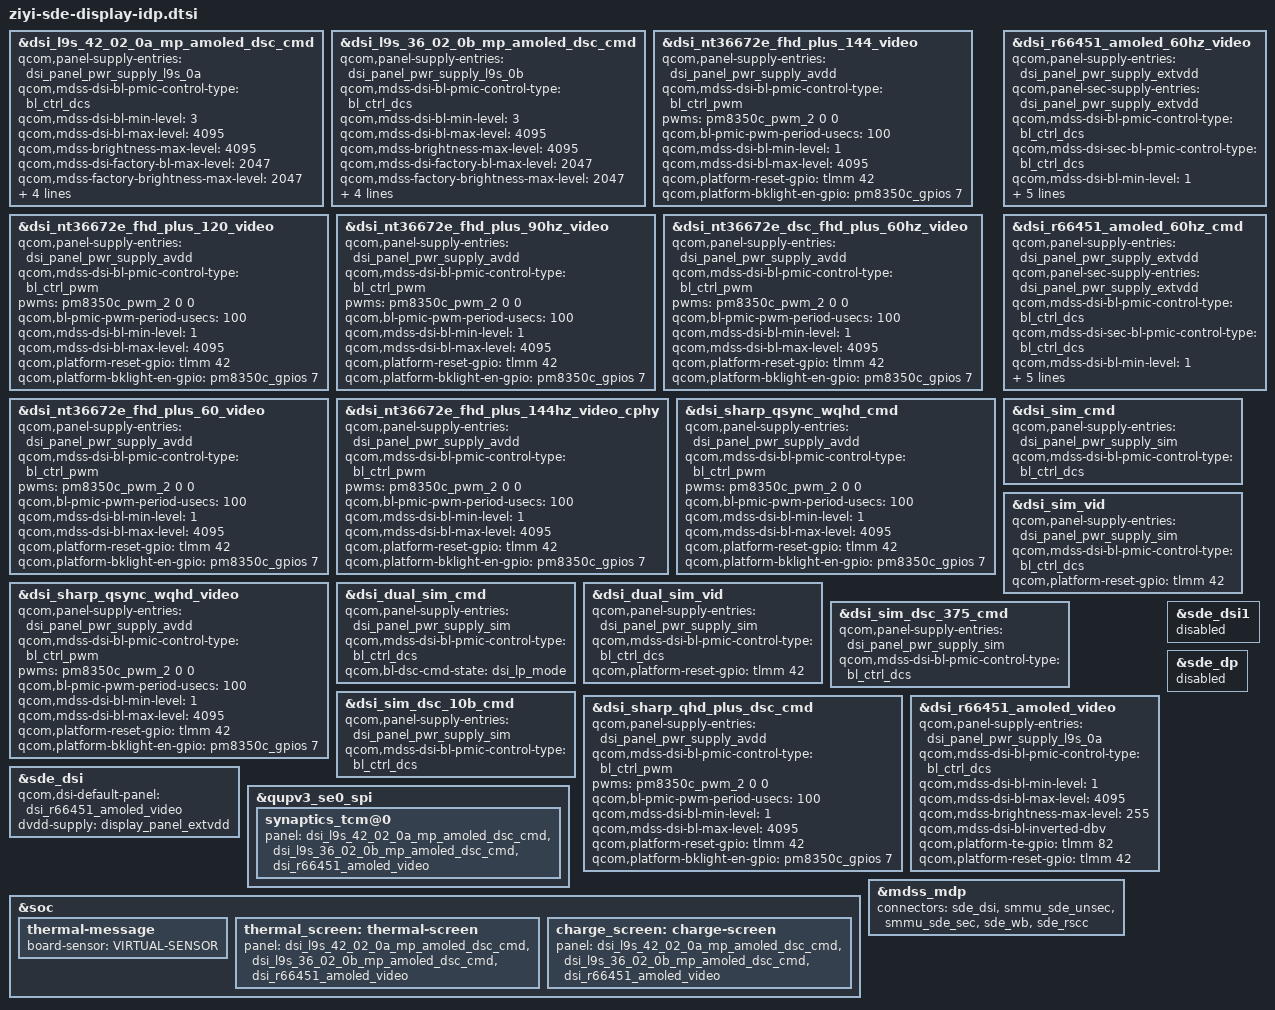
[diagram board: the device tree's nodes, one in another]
#include "diwali-sde-display.dtsi"

&dsi_l9s_42_02_0a_mp_amoled_dsc_cmd {
	qcom,panel-supply-entries = <&dsi_panel_pwr_supply_l9s_0a>;
	qcom,mdss-dsi-bl-pmic-control-type = "bl_ctrl_dcs";
	qcom,mdss-dsi-bl-min-level = <3>;
	qcom,mdss-dsi-bl-max-level = <4095>;
	qcom,mdss-brightness-max-level = <4095>;
	qcom,mdss-dsi-factory-bl-max-level = <2047>;
	qcom,mdss-factory-brightness-max-level = <2047>;
	qcom,mdss-brightness-init-level = <307>;
	qcom,mdss-dsi-bl-inverted-dbv;
	qcom,platform-te-gpio = <&tlmm 82 0>;
	qcom,platform-reset-gpio = <&tlmm 42 0>;
};

&dsi_l9s_36_02_0b_mp_amoled_dsc_cmd {
	qcom,panel-supply-entries = <&dsi_panel_pwr_supply_l9s_0b>;
	qcom,mdss-dsi-bl-pmic-control-type = "bl_ctrl_dcs";
	qcom,mdss-dsi-bl-min-level = <3>;
	qcom,mdss-dsi-bl-max-level = <4095>;
	qcom,mdss-brightness-max-level = <4095>;
	qcom,mdss-dsi-factory-bl-max-level = <2047>;
	qcom,mdss-factory-brightness-max-level = <2047>;
	qcom,mdss-brightness-init-level = <307>;
	qcom,mdss-dsi-bl-inverted-dbv;
	qcom,platform-te-gpio = <&tlmm 82 0>;
	qcom,platform-reset-gpio = <&tlmm 42 0>;
};

&dsi_nt36672e_fhd_plus_144_video {
	qcom,panel-supply-entries = <&dsi_panel_pwr_supply_avdd>;
	qcom,mdss-dsi-bl-pmic-control-type = "bl_ctrl_pwm";
	pwms = <&pm8350c_pwm_2 0 0>;
	qcom,bl-pmic-pwm-period-usecs = <100>;
	qcom,mdss-dsi-bl-min-level = <1>;
	qcom,mdss-dsi-bl-max-level = <4095>;
	qcom,platform-reset-gpio = <&tlmm 42 0>;
	qcom,platform-bklight-en-gpio = <&pm8350c_gpios 7 0>;
};

&dsi_nt36672e_fhd_plus_120_video {
	qcom,panel-supply-entries = <&dsi_panel_pwr_supply_avdd>;
	qcom,mdss-dsi-bl-pmic-control-type = "bl_ctrl_pwm";
	pwms = <&pm8350c_pwm_2 0 0>;
	qcom,bl-pmic-pwm-period-usecs = <100>;
	qcom,mdss-dsi-bl-min-level = <1>;
	qcom,mdss-dsi-bl-max-level = <4095>;
	qcom,platform-reset-gpio = <&tlmm 42 0>;
	qcom,platform-bklight-en-gpio = <&pm8350c_gpios 7 0>;
};

&dsi_nt36672e_fhd_plus_90hz_video {
	qcom,panel-supply-entries = <&dsi_panel_pwr_supply_avdd>;
	qcom,mdss-dsi-bl-pmic-control-type = "bl_ctrl_pwm";
	pwms = <&pm8350c_pwm_2 0 0>;
	qcom,bl-pmic-pwm-period-usecs = <100>;
	qcom,mdss-dsi-bl-min-level = <1>;
	qcom,mdss-dsi-bl-max-level = <4095>;
	qcom,platform-reset-gpio = <&tlmm 42 0>;
	qcom,platform-bklight-en-gpio = <&pm8350c_gpios 7 0>;
};

&dsi_nt36672e_dsc_fhd_plus_60hz_video {
	qcom,panel-supply-entries = <&dsi_panel_pwr_supply_avdd>;
	qcom,mdss-dsi-bl-pmic-control-type = "bl_ctrl_pwm";
	pwms = <&pm8350c_pwm_2 0 0>;
	qcom,bl-pmic-pwm-period-usecs = <100>;
	qcom,mdss-dsi-bl-min-level = <1>;
	qcom,mdss-dsi-bl-max-level = <4095>;
	qcom,platform-reset-gpio = <&tlmm 42 0>;
	qcom,platform-bklight-en-gpio = <&pm8350c_gpios 7 0>;
};

&dsi_nt36672e_fhd_plus_60_video {
	qcom,panel-supply-entries = <&dsi_panel_pwr_supply_avdd>;
	qcom,mdss-dsi-bl-pmic-control-type = "bl_ctrl_pwm";
	pwms = <&pm8350c_pwm_2 0 0>;
	qcom,bl-pmic-pwm-period-usecs = <100>;
	qcom,mdss-dsi-bl-min-level = <1>;
	qcom,mdss-dsi-bl-max-level = <4095>;
	qcom,platform-reset-gpio = <&tlmm 42 0>;
	qcom,platform-bklight-en-gpio = <&pm8350c_gpios 7 0>;
};

&dsi_nt36672e_fhd_plus_144hz_video_cphy {
	qcom,panel-supply-entries = <&dsi_panel_pwr_supply_avdd>;
	qcom,mdss-dsi-bl-pmic-control-type = "bl_ctrl_pwm";
	pwms = <&pm8350c_pwm_2 0 0>;
	qcom,bl-pmic-pwm-period-usecs = <100>;
	qcom,mdss-dsi-bl-min-level = <1>;
	qcom,mdss-dsi-bl-max-level = <4095>;
	qcom,platform-reset-gpio = <&tlmm 42 0>;
	qcom,platform-bklight-en-gpio = <&pm8350c_gpios 7 0>;
};

&dsi_sharp_qsync_wqhd_cmd {
	qcom,panel-supply-entries = <&dsi_panel_pwr_supply_avdd>;
	qcom,mdss-dsi-bl-pmic-control-type = "bl_ctrl_pwm";
	pwms = <&pm8350c_pwm_2 0 0>;
	qcom,bl-pmic-pwm-period-usecs = <100>;
	qcom,mdss-dsi-bl-min-level = <1>;
	qcom,mdss-dsi-bl-max-level = <4095>;
	qcom,platform-reset-gpio = <&tlmm 42 0>;
	qcom,platform-bklight-en-gpio = <&pm8350c_gpios 7 0>;
};

&dsi_sharp_qsync_wqhd_video {
	qcom,panel-supply-entries = <&dsi_panel_pwr_supply_avdd>;
	qcom,mdss-dsi-bl-pmic-control-type = "bl_ctrl_pwm";
	pwms = <&pm8350c_pwm_2 0 0>;
	qcom,bl-pmic-pwm-period-usecs = <100>;
	qcom,mdss-dsi-bl-min-level = <1>;
	qcom,mdss-dsi-bl-max-level = <4095>;
	qcom,platform-reset-gpio = <&tlmm 42 0>;
	qcom,platform-bklight-en-gpio = <&pm8350c_gpios 7 0>;
};

&dsi_r66451_amoled_60hz_video {
	qcom,panel-supply-entries = <&dsi_panel_pwr_supply_extvdd>;
	qcom,panel-sec-supply-entries = <&dsi_panel_pwr_supply_extvdd>;
	qcom,mdss-dsi-bl-pmic-control-type = "bl_ctrl_dcs";
	qcom,mdss-dsi-sec-bl-pmic-control-type = "bl_ctrl_dcs";
	qcom,mdss-dsi-bl-min-level = <1>;
	qcom,mdss-dsi-bl-max-level = <4095>;
	qcom,mdss-brightness-max-level = <8191>;
	qcom,mdss-dsi-bl-inverted-dbv;
	qcom,platform-reset-gpio = <&tlmm 42 0>;
	qcom,platform-sec-reset-gpio = <&tlmm 4 0>;
};

&dsi_r66451_amoled_60hz_cmd {
	qcom,panel-supply-entries = <&dsi_panel_pwr_supply_extvdd>;
	qcom,panel-sec-supply-entries = <&dsi_panel_pwr_supply_extvdd>;
	qcom,mdss-dsi-bl-pmic-control-type = "bl_ctrl_dcs";
	qcom,mdss-dsi-sec-bl-pmic-control-type = "bl_ctrl_dcs";
	qcom,mdss-dsi-bl-min-level = <1>;
	qcom,mdss-dsi-bl-max-level = <4095>;
	qcom,mdss-brightness-max-level = <8191>;
	qcom,mdss-dsi-bl-inverted-dbv;
	qcom,platform-reset-gpio = <&tlmm 42 0>;
	qcom,platform-sec-reset-gpio = <&tlmm 4 0>;
};

&dsi_sim_cmd {
	qcom,panel-supply-entries = <&dsi_panel_pwr_supply_sim>;
	qcom,mdss-dsi-bl-pmic-control-type = "bl_ctrl_dcs";
};

&dsi_sim_vid {
	qcom,panel-supply-entries = <&dsi_panel_pwr_supply_sim>;
	qcom,mdss-dsi-bl-pmic-control-type = "bl_ctrl_dcs";
	qcom,platform-reset-gpio = <&tlmm 42 0>;
};

&dsi_dual_sim_cmd {
	qcom,panel-supply-entries = <&dsi_panel_pwr_supply_sim>;
	qcom,mdss-dsi-bl-pmic-control-type = "bl_ctrl_dcs";
	qcom,bl-dsc-cmd-state = "dsi_lp_mode";
};

&dsi_dual_sim_vid {
	qcom,panel-supply-entries = <&dsi_panel_pwr_supply_sim>;
	qcom,mdss-dsi-bl-pmic-control-type = "bl_ctrl_dcs";
	qcom,platform-reset-gpio = <&tlmm 42 0>;
};

&dsi_sim_dsc_375_cmd {
	qcom,panel-supply-entries = <&dsi_panel_pwr_supply_sim>;
	qcom,mdss-dsi-bl-pmic-control-type = "bl_ctrl_dcs";
};

&dsi_sim_dsc_10b_cmd {
	qcom,panel-supply-entries = <&dsi_panel_pwr_supply_sim>;
	qcom,mdss-dsi-bl-pmic-control-type = "bl_ctrl_dcs";
};

&dsi_sharp_qhd_plus_dsc_cmd {
	qcom,panel-supply-entries = <&dsi_panel_pwr_supply_avdd>;
	qcom,mdss-dsi-bl-pmic-control-type = "bl_ctrl_pwm";
	pwms = <&pm8350c_pwm_2 0 0>;
	qcom,bl-pmic-pwm-period-usecs = <100>;
	qcom,mdss-dsi-bl-min-level = <1>;
	qcom,mdss-dsi-bl-max-level = <4095>;
	qcom,platform-reset-gpio = <&tlmm 42 0>;
	qcom,platform-bklight-en-gpio = <&pm8350c_gpios 7 0>;
};

&dsi_r66451_amoled_video {
	qcom,panel-supply-entries = <&dsi_panel_pwr_supply_l9s_0a>;
	qcom,mdss-dsi-bl-pmic-control-type = "bl_ctrl_dcs";
	qcom,mdss-dsi-bl-min-level = <1>;
	qcom,mdss-dsi-bl-max-level = <4095>;
	qcom,mdss-brightness-max-level = <255>;
	qcom,mdss-dsi-bl-inverted-dbv;
	qcom,platform-te-gpio = <&tlmm 82 0>;
	qcom,platform-reset-gpio = <&tlmm 42 0>;
};

&sde_dsi {
	qcom,dsi-default-panel = <&dsi_r66451_amoled_video>;
	dvdd-supply = <&display_panel_extvdd>;
};

&qupv3_se0_spi {
	synaptics_tcm@0 {
		panel = <&dsi_l9s_42_02_0a_mp_amoled_dsc_cmd
			&dsi_l9s_36_02_0b_mp_amoled_dsc_cmd
			&dsi_r66451_amoled_video>;
	};
};

&soc {
	thermal-message {
		board-sensor = "VIRTUAL-SENSOR";
	};
	thermal_screen: thermal-screen {
		panel = <&dsi_l9s_42_02_0a_mp_amoled_dsc_cmd
			&dsi_l9s_36_02_0b_mp_amoled_dsc_cmd
			&dsi_r66451_amoled_video>;
        };
	charge_screen: charge-screen {
		panel = <&dsi_l9s_42_02_0a_mp_amoled_dsc_cmd
			&dsi_l9s_36_02_0b_mp_amoled_dsc_cmd
			&dsi_r66451_amoled_video>;
	};
};

&sde_dsi1 {
	status = "disabled";
};

&sde_dp {
	status = "disabled";
};

&mdss_mdp {
	connectors = <&sde_dsi &smmu_sde_unsec &smmu_sde_sec &sde_wb &sde_rscc>;
};
